# STM32W108 register map
File version: 1.0
Registers are 32-bit, read-write, reset 0x0 unless marked. A register's access mark holds for its fields unless they carry their own. Offsets are from the block's base; lines under a group give offsets from that group; [hi:lo] are bit positions; {n}, {i} and the like mark numbered series; 'fields as' and 'values as' point back to an identical list; <NAME> marks a mode.

## Memory map
0x40000004 PWR size 0xBC19 — Power control
0x40000008 CLK size 0x4025 — Clock
0x4000002C RST size 0x1 — Reset event
0x40002038 MAC_TIM size 0x55 — MAC timer
0x40004028 GPIO_DBG size 0x7BDD — General purpose I/Os
0x4000402C FLASH size 0x43D4
0x40005000 MEM size 0x29 — Memory Control registers
0x40006000 WDG size 0x9 — Watchdog timer
0x4000600C SLPTMR size 0x4049 — Sleep timer
0x4000A800 TIM1 size 0x3851 — General purpose timer 1
0x4000A804 TIM2 size 0x484D — General purpose timer 2
0x4000A808 SC1 size 0x205D — Serial controller 1
0x4000A80C SC2 size 0x1859 — Serial controller 2
0x4000A810 ADC size 0x2815 — Analog to Digital Converter
0x4000A814 EXTI size 0x1405 — External interrupt/event controller
0x4000B000 GPIOA size 0x400 — General purpose I/Os
0x4000B400 GPIOB size 0x400 — General purpose I/Os
0x4000B800 GPIOC size 0x400 — General purpose I/Os
0x4000C000 SC2_DMA size 0x71 — Serial controller 2 (Direct memory access)
0x4000C040 SC2_SPI size 0x19 — Serial controller 2 (Serial peripheral interface)
0x4000C044 SC2_I2C size 0xD — Serial controller 2 (Serial peripheral interface)
0x4000C800 SC1_DMA size 0x71 — Serial controller 1 (Direct memory access)
0x4000C840 SC1_SPI size 0x19 — Serial controller 1 (Serial peripheral interface)
0x4000C844 SC1_I2C size 0xD — Serial controller 1 (Serial peripheral interface)
0x4000C848 SC1_UART size 0x25 — Serial controller 1 (Universal Asynchronous Receiver/Transmitter)
0xE000E000 NVIC size 0x1001 — Nested Vectored Interrupt Controller

## Interrupts
0 TIM1_IRQ (TIM1) — Timer 1 Interrupt
1 TIM2_IRQ (TIM2) — Timer 2 Interrupt
4 SLPTIM_IRQ (SLPTMR) — Sleep Timer Interrupt
5 SC1_IRQ (SC1) — Serial Controller 1 Interrupt
6 SC2_IRQ (SC2) — Serial Controller 2 Interrupt
8 MAC_TIM_IRQ (MAC_TIM) — MAC Timer Interrupt
11 ADC_IRQ (ADC) — ADC Interrupt
12 EXTIA_IRQ (EXTI) — EXTI port A interrupt
13 EXTIB_IRQ (EXTI) — EXTI port B interrupt
14 EXTIC_IRQ (EXTI) — EXTI port C interrupt
15 EXTID_IRQ (EXTI) — EXTI port D interrupt

## TIM1 — General purpose timer 1
Base 0x4000A800
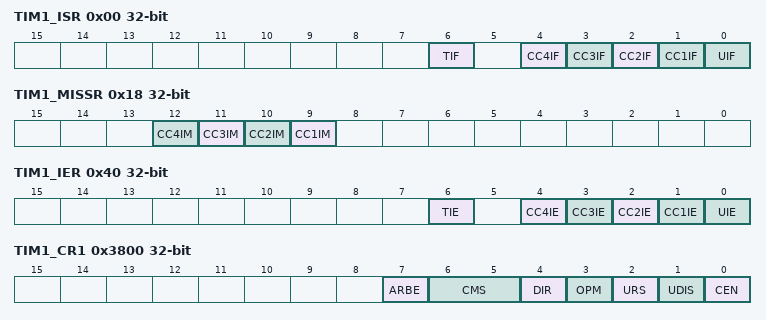
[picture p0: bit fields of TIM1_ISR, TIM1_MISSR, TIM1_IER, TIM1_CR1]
0x00 TIM1_ISR access per field — TIM Interrupt Status Register
  [6] TIF rw, [n] CC{n}IF rw (n=1..4), [0] UIF rw
0x18 TIM1_MISSR access per field — TIM interrupt missed register
  [n+8] CC{n}IM rw (n=1..4)
0x40 TIM1_IER — TIM Interrupt Enable Register
  [6] TIE, [n] CC{n}IE (n=1..4), [0] UIE
0x3800 TIM1_CR1 — control register 1
  [7] ARBE, [6:5] CMS, [4] DIR, [3] OPM, [2] URS, [1] UDIS, [0] CEN
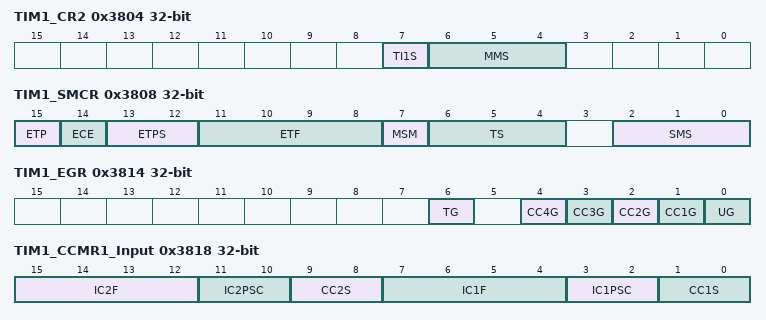
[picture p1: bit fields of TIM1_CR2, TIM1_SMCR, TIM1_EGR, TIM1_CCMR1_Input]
0x3804 TIM1_CR2 — control register 2
  [7] TI1S, [6:4] MMS
0x3808 TIM1_SMCR — slave Mode Control register
  [15] ETP, [14] ECE, [13:12] ETPS, [11:8] ETF, [7] MSM, [6:4] TS, [2:0] SMS
0x3814 TIM1_EGR wo — TIM event generation register
  [6] TG, [n] CC{n}G (n=1..4), [0] UG
0x3818 TIM1_CCMR1_Input — capture/compare mode register 1 (Input mode)
  [15:12] IC2F, [11:10] IC2PSC, [9:8] CC2S, [7:4] IC1F, [3:2] IC1PSC, [1:0] CC1S
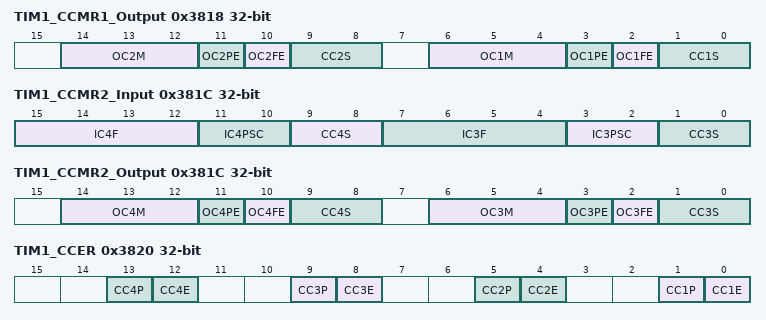
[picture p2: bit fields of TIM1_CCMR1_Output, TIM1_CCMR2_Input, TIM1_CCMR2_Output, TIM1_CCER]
0x3818 TIM1_CCMR1_Output (alternate view of TIM1_CCMR1_Input) — capture/compare mode register 1 (output mode)
  [14:12] OC2M, [11] OC2PE, [10] OC2FE, [9:8] CC2S, [6:4] OC1M, [3] OC1PE, [2] OC1FE, [1:0] CC1S
0x381C TIM1_CCMR2_Input — capture/compare mode register 2 (input mode)
  [15:12] IC4F, [11:10] IC4PSC, [9:8] CC4S, [7:4] IC3F, [3:2] IC3PSC, [1:0] CC3S
0x381C TIM1_CCMR2_Output (alternate view of TIM1_CCMR2_Input) — capture/compare mode register 2 (output mode)
  [14:12] OC4M, [11] OC4PE, [10] OC4FE, [9:8] CC4S, [6:4] OC3M, [3] OC3PE, [2] OC3FE, [1:0] CC3S
0x3820 TIM1_CCER — TIM capture/compare enable register
  [4n-3] CC{n}P (n=1..4), [4n-4] CC{n}E (n=1..4)
0x3824 TIM1_CNT — TIM counter register
  [15:0] CNT
0x3828 TIM1_PSC — TIM prescaler register
  [15:0] PSC
0x382C TIM1_ARR — TIM auto-reload register
  [15:0] ARR
0x3834 TIM1_CCR1 — IM capture/compare register 1
  [15:0] CCR
{0x3830+4i} TIM1_CCR{i} (i=2..4) — TIM capture/compare register {i}
  [15:0] CCR
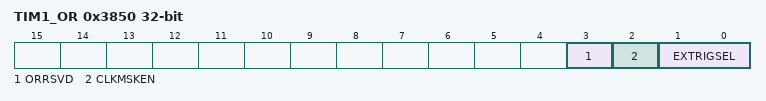
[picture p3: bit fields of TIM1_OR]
0x3850 TIM1_OR — TIM option register
  [3] ORRSVD, [2] CLKMSKEN, [1:0] EXTRIGSEL
